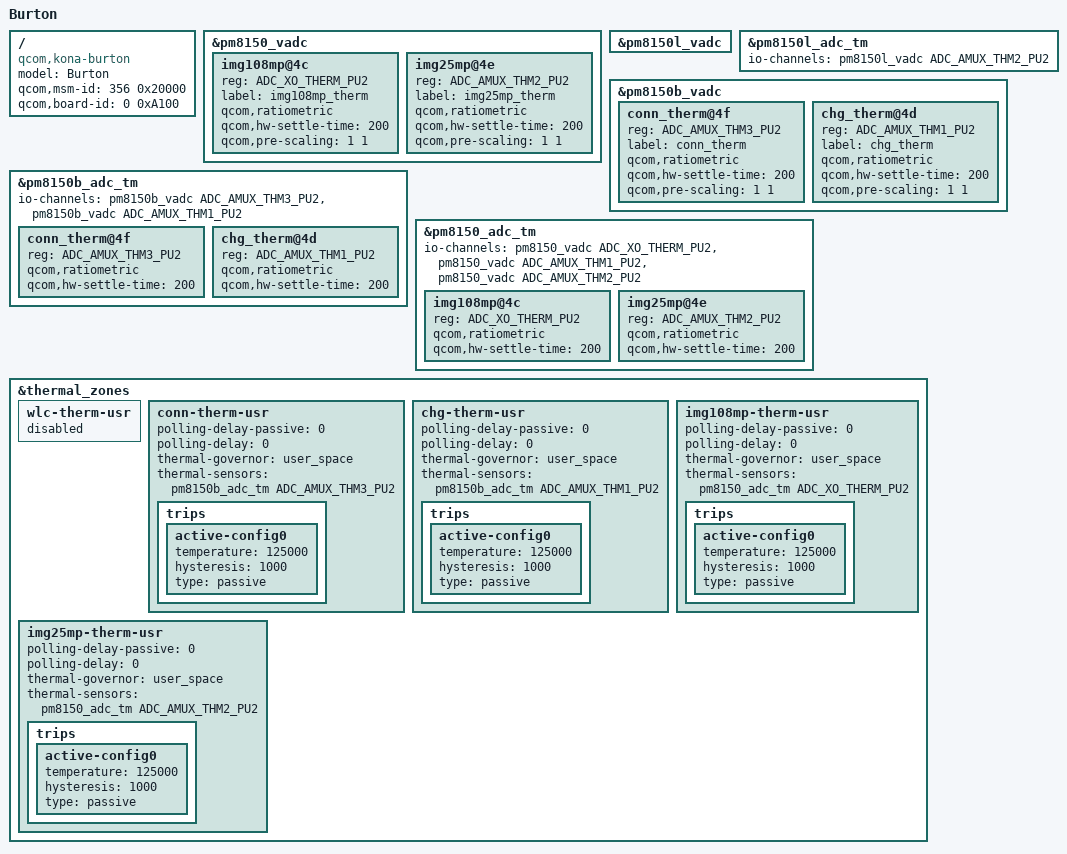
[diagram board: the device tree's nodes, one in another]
/* Copyright (c) 2019, The Linux Foundation. All rights reserved.
 *
 * This program is free software; you can redistribute it and/or modify
 * it under the terms of the GNU General Public License version 2 and
 * only version 2 as published by the Free Software Foundation.
 *
 * This program is distributed in the hope that it will be useful,
 * but WITHOUT ANY WARRANTY; without even the implied warranty of
 * MERCHANTABILITY or FITNESS FOR A PARTICULAR PURPOSE.  See the
 * GNU General Public License for more details.
 */

/dts-v1/;
/plugin/;

#include "kona-moto-common-overlay.dtsi"

/ {
	model = "Burton";
	compatible = "qcom,kona-burton", "qcom,kona-moto", "qcom,kona";
	qcom,msm-id = <356 0x20000>;
	qcom,board-id = <0 0xA100>;
};

/*
 * Burton HW rev EVT1 specific changes go here
 */
&pm8150_vadc {
	img108mp@4c {
		reg = <ADC_XO_THERM_PU2>;
		label = "img108mp_therm";
		qcom,ratiometric;
		qcom,hw-settle-time = <200>;
		qcom,pre-scaling = <1 1>;
	};

	img25mp@4e {
		reg = <ADC_AMUX_THM2_PU2>;
		label = "img25mp_therm";
		qcom,ratiometric;
		qcom,hw-settle-time = <200>;
		qcom,pre-scaling = <1 1>;
	};
};

&pm8150l_vadc {
	/delete-node/ img108mp@4d;
	/delete-node/ img25mp@4f;
};

&pm8150l_adc_tm {
	io-channels = <&pm8150l_vadc ADC_AMUX_THM2_PU2>;

	/delete-node/ img108mp@4d;
	/delete-node/ img25mp@4f;
};

&pm8150b_vadc {
	/delete-node/ chg_therm@4e;
	/delete-node/ wlc_therm@4d;

	conn_therm@4f {
		reg = <ADC_AMUX_THM3_PU2>;
		label = "conn_therm";
		qcom,ratiometric;
		qcom,hw-settle-time = <200>;
		qcom,pre-scaling = <1 1>;
	};

	chg_therm@4d {
		reg = <ADC_AMUX_THM1_PU2>;
		label = "chg_therm";
		qcom,ratiometric;
		qcom,hw-settle-time = <200>;
		qcom,pre-scaling = <1 1>;
	};
};

&pm8150b_adc_tm {
	io-channels = <&pm8150b_vadc ADC_AMUX_THM3_PU2>,
        <&pm8150b_vadc ADC_AMUX_THM1_PU2>;

	/delete-node/ wlc_therm@4d;
	/delete-node/ chg_therm@4e;

	conn_therm@4f {
		reg = <ADC_AMUX_THM3_PU2>;
		qcom,ratiometric;
		qcom,hw-settle-time = <200>;
	};

	chg_therm@4d {
		reg = <ADC_AMUX_THM1_PU2>;
		qcom,ratiometric;
		qcom,hw-settle-time = <200>;
	};
};

&pm8150_adc_tm {
	io-channels = <&pm8150_vadc ADC_XO_THERM_PU2>,
			<&pm8150_vadc ADC_AMUX_THM1_PU2>,
			<&pm8150_vadc ADC_AMUX_THM2_PU2>;

	img108mp@4c {
		reg = <ADC_XO_THERM_PU2>;
		qcom,ratiometric;
		qcom,hw-settle-time = <200>;
	};

	img25mp@4e {
		reg = <ADC_AMUX_THM2_PU2>;
		qcom,ratiometric;
		qcom,hw-settle-time = <200>;
	};
};

&thermal_zones {
	wlc-therm-usr {
		status = "disabled";
	};

	conn-therm-usr {
		polling-delay-passive = <0>;
		polling-delay = <0>;
		thermal-governor = "user_space";
		thermal-sensors = <&pm8150b_adc_tm ADC_AMUX_THM3_PU2>;
		trips {
			active-config0 {
				temperature = <125000>;
				hysteresis = <1000>;
				type = "passive";
			};
		};
	};

	chg-therm-usr {
		polling-delay-passive = <0>;
		polling-delay = <0>;
		thermal-governor = "user_space";
		thermal-sensors = <&pm8150b_adc_tm ADC_AMUX_THM1_PU2>;
		trips {
			active-config0 {
				temperature = <125000>;
				hysteresis = <1000>;
				type = "passive";
			};
		};
	};

	img108mp-therm-usr {
		polling-delay-passive = <0>;
		polling-delay = <0>;
		thermal-governor = "user_space";
		thermal-sensors = <&pm8150_adc_tm ADC_XO_THERM_PU2>;
		trips {
			active-config0 {
				temperature = <125000>;
				hysteresis = <1000>;
				type = "passive";
			};
		};
	};

	img25mp-therm-usr {
		polling-delay-passive = <0>;
		polling-delay = <0>;
		thermal-governor = "user_space";
		thermal-sensors = <&pm8150_adc_tm ADC_AMUX_THM2_PU2>;
		trips {
			active-config0 {
				temperature = <125000>;
				hysteresis = <1000>;
				type = "passive";
			};
		};
	};
};
